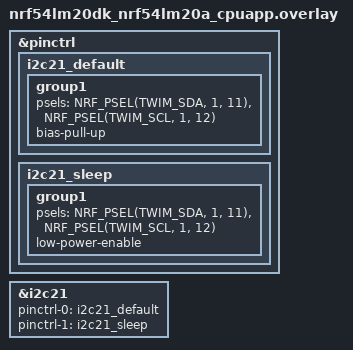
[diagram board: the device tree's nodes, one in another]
/*
 * Copyright (c) 2025 Nordic Semiconductor ASA
 *
 * SPDX-License-Identifier: LicenseRef-Nordic-5-Clause
 */

&pinctrl {
	i2c21_default: i2c21_default {
		group1 {
			psels = <NRF_PSEL(TWIM_SDA, 1, 11)>,
				<NRF_PSEL(TWIM_SCL, 1, 12)>;
			bias-pull-up;
		};
	};

	i2c21_sleep: i2c21_sleep {
		group1 {
			psels = <NRF_PSEL(TWIM_SDA, 1, 11)>,
				<NRF_PSEL(TWIM_SCL, 1, 12)>;
			low-power-enable;
		};
	};
};

i2c_npm13xx: &i2c21 {
	status = "okay";
	pinctrl-0 = <&i2c21_default>;
	pinctrl-1 = <&i2c21_sleep>;
	pinctrl-names = "default", "sleep";
};
